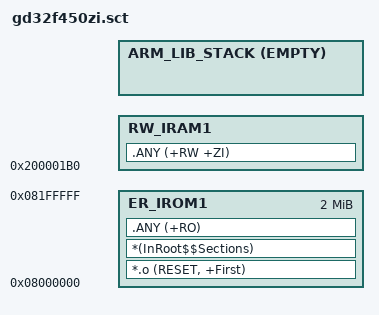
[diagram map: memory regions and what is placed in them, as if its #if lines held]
#! armclang -E --target=arm-arm-none-eabi -x c -mcpu=cortex-m4
; *************************************************************
; *** Scatter-Loading Description File generated by uVision ***
; *****

#if !defined(MBED_APP_START)
  #define MBED_APP_START 0x08000000
#endif

#if !defined(MBED_APP_SIZE)
  #define MBED_APP_SIZE 0x200000
#endif

#if !defined(MBED_CONF_TARGET_BOOT_STACK_SIZE)
#  if defined(MBED_BOOT_STACK_SIZE)
#    define MBED_CONF_TARGET_BOOT_STACK_SIZE MBED_BOOT_STACK_SIZE
#  else
#    define MBED_CONF_TARGET_BOOT_STACK_SIZE 0x400
#  endif
#endif

#define Stack_Size MBED_CONF_TARGET_BOOT_STACK_SIZE

LR_IROM1 MBED_APP_START MBED_APP_SIZE  {    ; load region size_region (3*1024K)

  ER_IROM1 MBED_APP_START MBED_APP_SIZE  {  ; load address = execution address
   *.o (RESET, +First)
   *(InRoot$$Sections)
   .ANY (+RO)
  }

  ; 107 vectors (16 core + 91 peripheral) * 4 bytes = 428 bytes to reserve (0x1B0, 8-byte aligned)
  RW_IRAM1 (0x20000000+0x1B0) (0x30000-0x1B0-Stack_Size)  {  ; RW data
   .ANY (+RW +ZI)
  }

  ARM_LIB_STACK 0x20000000+0x30000 EMPTY -Stack_Size { ; Stack region growing down
  }
}
